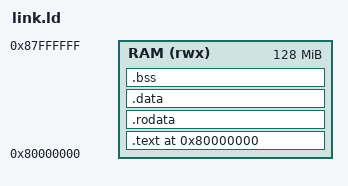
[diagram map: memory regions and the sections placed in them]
/* Linker script for QEMU RISC-V virt machine */
OUTPUT_ARCH(riscv)
ENTRY(_start)

MEMORY
{
    RAM (rwx) : ORIGIN = 0x80000000, LENGTH = 128M
}

SECTIONS
{
    . = 0x80000000;

    .text : {
        *(.text._start)
        *(.text*)
    } > RAM

    .rodata : {
        *(.rodata*)
    } > RAM

    .data : {
        *(.data*)
    } > RAM

    .bss : {
        *(.bss*)
        *(COMMON)
    } > RAM

    . = ALIGN(16);
    . = . + 0x4000;
    _stack_top = .;
}
